# apollo2 register map
Vendor: Ambiq Micro; Series: Apollo; File version: 1.0
CPU: CM4 r1p0, little endian, MPU, FPU, 3 interrupt priority bits
Registers are 32-bit, read-write, reset 0x0 unless marked. A register's access mark holds for its fields unless they carry their own. Offsets are from the block's base; [hi:lo] are bit positions; {n}, {i} and the like mark numbered series.

## PWRCTRL — PWR Controller Register Bank
Base 0x40021000
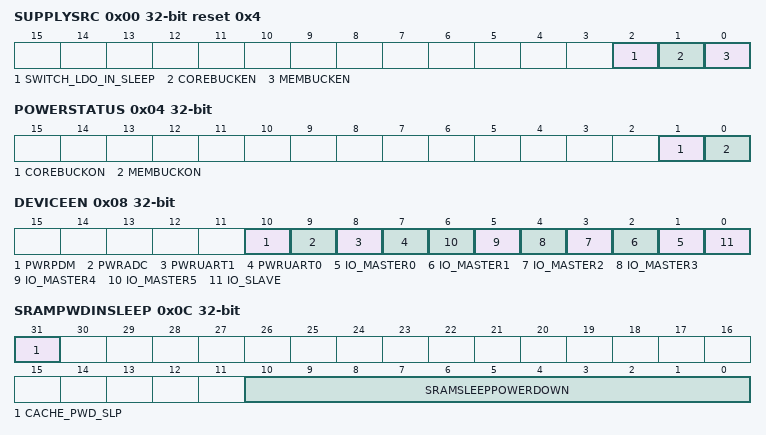
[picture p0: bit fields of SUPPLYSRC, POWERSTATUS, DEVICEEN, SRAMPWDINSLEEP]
0x00 SUPPLYSRC reset 0x4 — Memory and Core Voltage Supply Source Select Register
  [2] SWITCH_LDO_IN_SLEEP — Switches the CORE DOMAIN from BUCK mode (if enabled) to LDO when CPU is in DEEP SLEEP. If all the devices are off then this does not matter and LDO (low power mode) is used
    1=EN (Automatically switch from CORE BUCK to CORE LDO when CPU is in DEEP SLEEP value.)
  [1] COREBUCKEN — Enables and Selects the Core Buck as the supply for the low-voltage power domain.
    1=EN (Enable the Core Buck for the low-voltage power domain. value.)
  [0] MEMBUCKEN — Enables and select the Memory Buck as the supply for the Flash and SRAM power domain.
    1=EN (Enable the Memory Buck as the supply for flash and SRAM. value.)
0x04 POWERSTATUS — Power Status Register for MCU supplies and peripherals
  [1] COREBUCKON — Indicates whether the Core low-voltage domain is supplied from the LDO or the Buck.
    0=LDO (Indicates the the LDO is supplying the Core low-voltage. value.); 1=BUCK (Indicates the the Buck is supplying the Core low-voltage. value.)
  [0] MEMBUCKON — Indicate whether the Memory power domain is supplied from the LDO or the Buck.
    0=LDO (Indicates the LDO is supplying the memory power domain. value.); 1=BUCK (Indicates the Buck is supplying the memory power domain. value.)
0x08 DEVICEEN — DEVICE ENABLES for SHELBY
  [10] PWRPDM — Enable PDM Digital Block
    1=EN (Enable PDM value.); 0=DIS (Disables PDM value.)
  [9] PWRADC — Enable ADC Digital Block
    1=EN (Enable ADC value.); 0=DIS (Disables ADC value.)
  [8] PWRUART1 — Enable UART 1
    1=EN (Enable UART 1 value.); 0=DIS (Disables UART 1 value.)
  [7] PWRUART0 — Enable UART 0
    1=EN (Enable UART 0 value.); 0=DIS (Disables UART 0 value.)
  [n+1] IO_MASTER{n} (n=0..5) — Enable IO MASTER {n}
    1=EN (Enable IO MASTER {n} value.); 0=DIS (Disables IO MASTER {n} value.)
  [0] IO_SLAVE — Enable IO SLAVE
    1=EN (Enable IO SLAVE value.); 0=DIS (Disables IO SLAVE value.)
0x0C SRAMPWDINSLEEP — Powerdown an SRAM Banks in Deep Sleep mode
  [31] CACHE_PWD_SLP — Enable CACHE BANKS to power down in deep sleep
    1=EN (CACHE BANKS POWER DOWN in CORE SLEEP value.); 0=DIS (CACHE BANKS STAYS in Retention in CORE SLEEP value.)
  [10:0] SRAMSLEEPPOWERDOWN — Selects which SRAM banks are powered down in deep sleep mode, causing the contents of the bank to be lost.
    0=NONE (All banks retained value.); 1=GROUP0_SRAM0 (0KB-8KB SRAM value.); 2=GROUP0_SRAM1 (8KB-16KB SRAM value.); 4=GROUP0_SRAM2 (16KB-24KB SRAM value.); 8=GROUP0_SRAM3 (24KB-32KB SRAM value.); 16=GROUP1 (32KB-64KB SRAMs value.); 32=GROUP2 (64KB-96KB SRAMs value.); 64=GROUP3 (96KB-128KB SRAMs value.); 128=GROUP4 (128KB-160KB SRAMs value.); 0x100=GROUP5 (160KB-192KB SRAMs value.); 0x200=GROUP6 (192KB-224KB SRAMs value.); 0x400=GROUP7 (224KB-256KB SRAMs value.); 3=SRAM16K (Do not Retain lower 16KB value.); 15=SRAM32K (Do not Retain lower 32KB value.); 31=SRAM64K (Do not Retain lower 64KB value.); 127=SRAM128K (Do not Retain lower 128KB value.); 0x7FE=ALLBUTLOWER8K (All banks but lower 8k powered down. value.); 0x7FC=ALLBUTLOWER16K (All banks but lower 16k powered down. value.); 0x7F8=ALLBUTLOWER24K (All banks but lower 24k powered down. value.); 0x7F0=ALLBUTLOWER32K (All banks but lower 32k powered down. value.); 0x7E0=ALLBUTLOWER64K (All banks but lower 64k powered down. value.); 0x780=ALLBUTLOWER128K (All banks but lower 128k powered down. value.); 0x7FF=ALL (All banks powered down. value.)
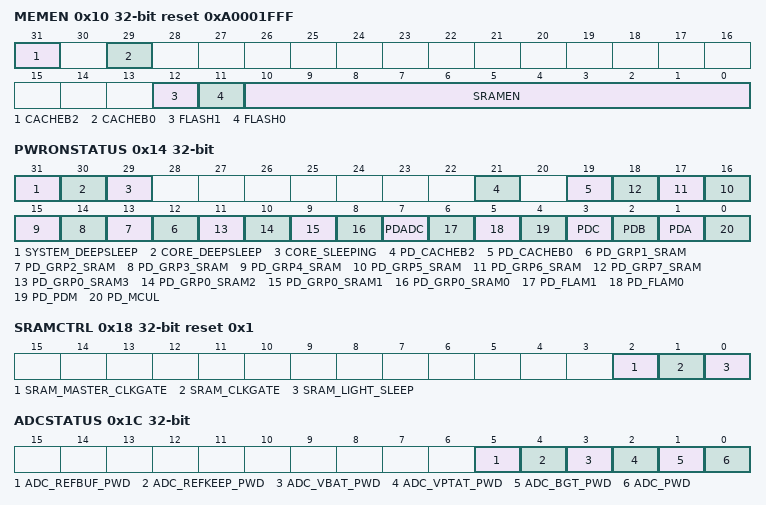
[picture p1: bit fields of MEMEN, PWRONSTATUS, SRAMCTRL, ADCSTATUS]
0x10 MEMEN reset 0xA0001FFF — Disables individual banks of the MEMORY array
  [31] CACHEB2 — Enable CACHE BANK 2
    1=EN (Enable CACHE BANK 2 value.); 0=DIS (Disable CACHE BANK 2 value.)
  [29] CACHEB0 — Enable CACHE BANK 0
    1=EN (Enable CACHE BANK 0 value.); 0=DIS (Disable CACHE BANK 0 value.)
  [12] FLASH1 — Enable FLASH1
    1=EN (Enable FLASH1 value.); 0=DIS (Disables FLASH1 value.)
  [11] FLASH0 — Enable FLASH 0
    1=EN (Enable FLASH 0 value.); 0=DIS (Disables FLASH 0 value.)
  [10:0] SRAMEN — Enables power for selected SRAM banks (else an access to its address space to generate a Hard Fault).
    0=NONE (All banks disabled value.); 1=GROUP0_SRAM0 (0KB-8KB SRAM value.); 2=GROUP0_SRAM1 (8KB-16KB SRAM value.); 4=GROUP0_SRAM2 (16KB-24KB SRAM value.); 8=GROUP0_SRAM3 (24KB-32KB SRAM value.); 16=GROUP1 (32KB-64KB SRAMs value.); 32=GROUP2 (64KB-96KB SRAMs value.); 64=GROUP3 (96KB-128KB SRAMs value.); 128=GROUP4 (128KB-160KB SRAMs value.); 0x100=GROUP5 (160KB-192KB SRAMs value.); 0x200=GROUP6 (192KB-224KB SRAMs value.); 0x400=GROUP7 (224KB-256KB SRAMs value.); 3=SRAM16K (ENABLE lower 16KB value.); 15=SRAM32K (ENABLE lower 32KB value.); 31=SRAM64K (ENABLE lower 64KB value.); 127=SRAM128K (ENABLE lower 128KB value.); 0x7FF=SRAM256K (ENABLE lower 256KB value.)
0x14 PWRONSTATUS — POWER ON Status
  [31] SYSTEM_DEEPSLEEP — This bit is 1 if SYSTEM has been in Deep Sleep. Write '1' to this bit to clear it.
  [30] CORE_DEEPSLEEP — This bit is 1 if CORE has been in Deep Sleep. Write '1' to this bit to clear it.
  [29] CORE_SLEEPING — This bit is 1 if CORE has been in SLEEP State. Write '1' to this bit to clear it.
  [21] PD_CACHEB2 — This bit is 1 if power is supplied to CACHE BANK 2
  [19] PD_CACHEB0 — This bit is 1 if power is supplied to CACHE BANK 0
  [n+11] PD_GRP{n}_SRAM (n=1..7) — This bit is 1 if power is supplied to SRAM domain PD_GRP{n}
  [11] PD_GRP0_SRAM3 — This bit is 1 if power is supplied to SRAM domain PD_SRAM0_3
  [10] PD_GRP0_SRAM2 — This bit is 1 if power is supplied to SRAM domain PD_SRAM0_2
  [9] PD_GRP0_SRAM1 — This bit is 1 if power is supplied to SRAM domain SRAM0_1
  [8] PD_GRP0_SRAM0 — This bit is 1 if power is supplied to SRAM domain SRAM0_0
  [7] PDADC — This bit is 1 if power is supplied to domain PD_ADC
  [6] PD_FLAM1 — This bit is 1 if power is supplied to domain PD_FLAM1
  [5] PD_FLAM0 — This bit is 1 if power is supplied to domain PD_FLAM0
  [4] PD_PDM — This bit is 1 if power is supplied to domain PD_PDM
  [3] PDC — This bit is 1 if power is supplied to power domain C, which supplies IOM3-5.
  [2] PDB — This bit is 1 if power is supplied to power domain B, which supplies IOM0-2.
  [1] PDA — This bit is 1 if power is supplied to power domain A, which supplies IOS and UART0,1.
  [0] PD_MCUL — This bit is 1 if power is supplied to power domain PD_MCUL.
0x18 SRAMCTRL reset 0x1 — SRAM Control register
  [2] SRAM_MASTER_CLKGATE — Enables top-level clock gating in the SRAM block. This bit should be enabled for lowest power operation.
    1=EN (Enable Master SRAM Clock Gate value.); 0=DIS (Disables Master SRAM Clock Gating value.)
  [1] SRAM_CLKGATE — Enables individual per-RAM clock gating in the SRAM block. This bit should be enabled for lowest power operation.
    1=EN (Enable Individual SRAM Clock Gating value.); 0=DIS (Disables Individual SRAM Clock Gating value.)
  [0] SRAM_LIGHT_SLEEP — Enable LS (light sleep) of cache RAMs. When this bit is set, the RAMS will be put into light sleep mode while inactive. NOTE: if the SRAM is actively used, this may have an adverse affect on power since entering/exiting LS mode may consume more power than would be saved.
    1=EN (Enable LIGHT SLEEP for SRAMs value.); 0=DIS (Disables LIGHT SLEEP for SRAMs value.)
0x1C ADCSTATUS — Power Status Register for ADC Block
  [5] ADC_REFBUF_PWD — This bit indicates that the ADC REFBUF is powered down
  [4] ADC_REFKEEP_PWD — This bit indicates that the ADC REFKEEP is powered down
  [3] ADC_VBAT_PWD — This bit indicates that the ADC VBAT resistor divider is powered down
  [2] ADC_VPTAT_PWD — This bit indicates that the ADC temperature sensor input buffer is powered down
  [1] ADC_BGT_PWD — This bit indicates that the ADC Band Gap is powered down
  [0] ADC_PWD — This bit indicates that the ADC is powered down
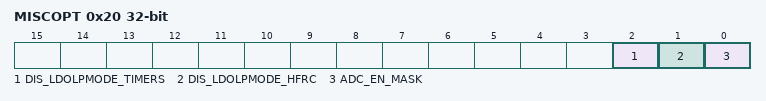
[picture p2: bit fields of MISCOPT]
0x20 MISCOPT — Power Optimization Control Bits
  [2] DIS_LDOLPMODE_TIMERS — Setting this bit will enable the MEM LDO to be in LPMODE during deep sleep even when the ctimers or stimers are running
  [1] DIS_LDOLPMODE_HFRC — Setting this bit will enable the Core LDO to be in LPMODE during deep sleep even when HFRC is enabled.
  [0] ADC_EN_MASK — Control Bit to mask the ADC_EN in the adc_pwr_down equation.
